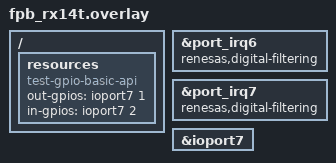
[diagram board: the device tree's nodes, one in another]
/*
 * Copyright (c) 2026 Renesas Electronics Corporation.
 *
 * SPDX-License-Identifier: Apache-2.0
 */

/ {
	resources {
		compatible = "test-gpio-basic-api";
		out-gpios = <&ioport7 1 0>; /* P71 */
		in-gpios = <&ioport7 2 0>; /* P72 */
	};
};

&port_irq6 {
	renesas,digital-filtering;
	status = "okay";
};

&port_irq7 {
	renesas,digital-filtering;
	status = "okay";
};

&ioport7 {
	status = "okay";
};
